AUTOSAR XML (schema 4-2-2)
package /ComponentTypes
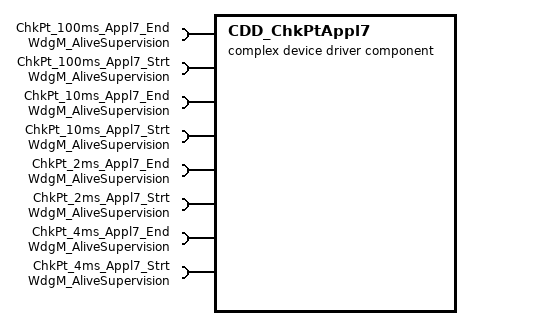
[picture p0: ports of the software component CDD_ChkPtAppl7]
  complex device driver sw component type CDD_ChkPtAppl7
    8 x require port, all with client-com-spec=CheckpointReached, required-interface=WdgM_AliveSupervision:
      ChkPt_100ms_Appl7_End
      ChkPt_100ms_Appl7_Strt
      ChkPt_10ms_Appl7_End
      ChkPt_10ms_Appl7_Strt
      ChkPt_2ms_Appl7_End
      ChkPt_2ms_Appl7_Strt
      ChkPt_4ms_Appl7_End
      ChkPt_4ms_Appl7_Strt
    behavior CDD_ChkPtAppl7_InternalBehavior
      8 x timing event:
        TMT_ChkPt_100msAppl7End: start-on-event=ChkPt_100msAppl7End, period=0.1
        TMT_ChkPt_100msAppl7Strt: start-on-event=ChkPt_100msAppl7Strt, period=0.1
        TMT_ChkPt_10msAppl7End: start-on-event=ChkPt_10msAppl7End, period=0.01
        TMT_ChkPt_10msAppl7Strt: start-on-event=ChkPt_10msAppl7Strt, period=0.01
        TMT_ChkPt_2msAppl7End: start-on-event=ChkPt_2msAppl7End, period=0.002
        TMT_ChkPt_2msAppl7Strt: start-on-event=ChkPt_2msAppl7Strt, period=0.002
        TMT_ChkPt_4msAppl7End: start-on-event=ChkPt_4msAppl7End, period=0.004
        TMT_ChkPt_4msAppl7Strt: start-on-event=ChkPt_4msAppl7Strt, period=0.004
      port-api-options:
        enable-take-address=false, error-handling=NO-TRANSFORMER-ERROR-HANDLING, indirect-api=false, port=ChkPt_100ms_Appl7_End
        enable-take-address=false, error-handling=NO-TRANSFORMER-ERROR-HANDLING, indirect-api=false, port=ChkPt_100ms_Appl7_Strt
        enable-take-address=false, error-handling=NO-TRANSFORMER-ERROR-HANDLING, indirect-api=false, port=ChkPt_10ms_Appl7_End
        enable-take-address=false, error-handling=NO-TRANSFORMER-ERROR-HANDLING, indirect-api=false, port=ChkPt_10ms_Appl7_Strt
        enable-take-address=false, error-handling=NO-TRANSFORMER-ERROR-HANDLING, indirect-api=false, port=ChkPt_2ms_Appl7_End
        enable-take-address=false, error-handling=NO-TRANSFORMER-ERROR-HANDLING, indirect-api=false, port=ChkPt_2ms_Appl7_Strt
        enable-take-address=false, error-handling=NO-TRANSFORMER-ERROR-HANDLING, indirect-api=false, port=ChkPt_4ms_Appl7_End
        enable-take-address=false, error-handling=NO-TRANSFORMER-ERROR-HANDLING, indirect-api=false, port=ChkPt_4ms_Appl7_Strt
      8 x runnable:
        ChkPt_100msAppl7End
          sync call SC_ChkPt_100ms_Appl7_End_CheckpointReached: operation=ChkPt_100ms_Appl7_End.CheckpointReached, timeout=0
        ChkPt_100msAppl7Strt
          sync call SC_ChkPt_100ms_Appl7_Strt_CheckpointReached: operation=ChkPt_100ms_Appl7_Strt.CheckpointReached, timeout=0
        ChkPt_10msAppl7End
          sync call SC_ChkPt_10ms_Appl7_End_CheckpointReached: operation=ChkPt_10ms_Appl7_End.CheckpointReached, timeout=0
        ChkPt_10msAppl7Strt
          sync call SC_ChkPt_10ms_Appl7_Strt_CheckpointReached: operation=ChkPt_10ms_Appl7_Strt.CheckpointReached, timeout=0
        ChkPt_2msAppl7End
          sync call SC_ChkPt_2ms_Appl7_End_CheckpointReached: operation=ChkPt_2ms_Appl7_End.CheckpointReached, timeout=0
        ChkPt_2msAppl7Strt
          sync call SC_ChkPt_2ms_Appl7_Strt_CheckpointReached: operation=ChkPt_2ms_Appl7_Strt.CheckpointReached, timeout=0
        ChkPt_4msAppl7End
          sync call SC_ChkPt_4ms_Appl7_End_CheckpointReached: operation=ChkPt_4ms_Appl7_End.CheckpointReached, timeout=0
        ChkPt_4msAppl7Strt
          sync call SC_ChkPt_4ms_Appl7_Strt_CheckpointReached: operation=ChkPt_4ms_Appl7_Strt.CheckpointReached, timeout=0
  swc implementation CDD_ChkPtAppl7_Implementation: behavior=CDD_ChkPtAppl7_InternalBehavior
    code-descriptors:
      code Default: artifact-descriptors=autosar-engineering-object={short-label=Default, category=SWSRC}
